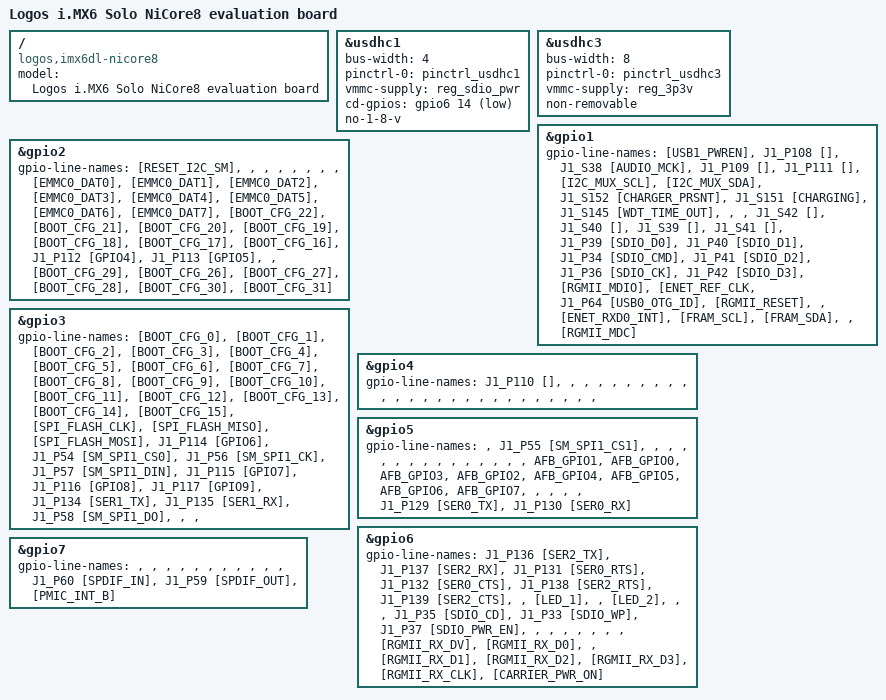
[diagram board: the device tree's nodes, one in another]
// SPDX-License-Identifier: GPL-2.0 OR X11
/*
 * Copyright 2015 Boundary Devices, Inc.
 * Copyright 2021 Logos Payment Solutions A/S
 */

/dts-v1/;

#include "imx6dl.dtsi"
#include "imx6qdl-nicore8.dtsi"

/ {
	model = "Logos i.MX6 Solo NiCore8 evaluation board";
	compatible = "logos,imx6dl-nicore8", "fsl,imx6dl";
};

/* USDHC1, SD Card */
&usdhc1 {
        pinctrl-names = "default";
        bus-width = <4>;
        pinctrl-0 = <&pinctrl_usdhc1>;
        vmmc-supply = <&reg_sdio_pwr>;
        cd-gpios = <&gpio6 14 GPIO_ACTIVE_LOW>;
	no-1-8-v;
        status = "okay";
};

/* USDHC3, eMMC */
&usdhc3 {
        pinctrl-names = "default";
        bus-width = <8>;
        pinctrl-0 = <&pinctrl_usdhc3>;
        vmmc-supply = <&reg_3p3v>;
        non-removable;
        status = "okay";
};

/* 
 * Purpose in GPIO naming below corresponds to schematic:
 * PCB17381-SCHE-401148-00 'PCB17381 NiCore8 SMARC 1.1 Module'
 * PCB18091-SCHE-401264-00 'PCB18091 SMARC Test Carrier'
 */

&gpio1 {
	gpio-line-names =
		"[USB1_PWREN]", // GPIO_0 GPIO1_IO00 0
		"J1_P108 []", // GPIO_1 GPIO1_IO01 1
		"J1_S38 [AUDIO_MCK]", // GPIO_2 GPIO1_IO02 2
		"J1_P109 []", // GPIO_3 GPIO1_IO03 3
		"J1_P111 []", // GPIO_4 GPIO1_IO04 4
		"[I2C_MUX_SCL]", // GPIO_5 GPIO1_IO05 5
		"[I2C_MUX_SDA]", // GPIO_6 GPIO1_IO06 6
		"J1_S152 [CHARGER_PRSNT]", // GPIO_7 GPIO1_IO07 7
		"J1_S151 [CHARGING]", // GPIO_8 GPIO1_IO08 8
		"J1_S145 [WDT_TIME_OUT]", // GPIO_9 GPIO1_IO09 9
		"", // SD2_CLK GPIO1_IO10 10
		"", // SD2_CMD GPIO1_IO11 11
		"J1_S42 []", // SD2_DAT3 GPIO1_IO12 12
		"J1_S40 []", // SD2_DAT2 GPIO1_IO13 13
		"J1_S39 []", // SD2_DAT1 GPIO1_IO14 14
		"J1_S41 []", // SD2_DAT0 GPIO1_IO15 15
		"J1_P39 [SDIO_D0]", // SD1_DAT0 GPIO1_IO16 16
		"J1_P40 [SDIO_D1]", // SD1_DAT1 GPIO1_IO17 17
		"J1_P34 [SDIO_CMD]", // SD1_CMD GPIO1_IO18 18
		"J1_P41 [SDIO_D2]", // SD1_DAT2 GPIO1_IO19 19
		"J1_P36 [SDIO_CK]", // SD1_CLK GPIO1_IO20 20
		"J1_P42 [SDIO_D3]", // SD1_DAT3 GPIO1_IO21 21
		"[RGMII_MDIO]", // ENET_MDIO GPIO1_IO22 22
		"[ENET_REF_CLK", // ENET_REF_CLK GPIO1_IO23 23
		"J1_P64 [USB0_OTG_ID]", // ENET_RX_ER GPIO1_IO24 24
		"[RGMII_RESET]", // ENET_CRS_DV GPIO1_IO25 25
		"", // ENET_RXD1 GPIO1_IO26 26
		"[ENET_RXD0_INT]", // ENET_RXD0 GPIO1_IO27 27
		"[FRAM_SCL]", // ENET_TX_EN GPIO1_IO28 28
		"[FRAM_SDA]", // ENET_TXD1 GPIO1_IO29 29
		"", // ENET_TXD0 GPIO1_IO30 30
		"[RGMII_MDC]"; // ENET_MDC GPIO1_IO31 31
};

&gpio2 {
	gpio-line-names =
		"[RESET_I2C_SM]", // NANDF_D0 GPIO2_IO00 32
		"", // NANDF_D1 GPIO2_IO01 33
		"", // NANDF_D2 GPIO2_IO02 34
		"", // NANDF_D3 GPIO2_IO03 35
		"", // NANDF_D4 GPIO2_IO04 36
		"", // NANDF_D5 GPIO2_IO05 37
		"", // NANDF_D6 GPIO2_IO06 38
		"", // NANDF_D7 GPIO2_IO07 39
		"[EMMC0_DAT0]", // SD4_DAT0 GPIO2_IO08 40
		"[EMMC0_DAT1]", // SD4_DAT1 GPIO2_IO09 41
		"[EMMC0_DAT2]", // SD4_DAT2 GPIO2_IO10 42
		"[EMMC0_DAT3]", // SD4_DAT3 GPIO2_IO11 43
		"[EMMC0_DAT4]", // SD4_DAT4 GPIO2_IO12 44
		"[EMMC0_DAT5]", // SD4_DAT5 GPIO2_IO13 45
		"[EMMC0_DAT6]", // SD4_DAT6 GPIO2_IO14 46
		"[EMMC0_DAT7]", // SD4_DAT7 GPIO2_IO15 47
		"[BOOT_CFG_22]", // EIM_A22 GPIO2_IO16 48
		"[BOOT_CFG_21]", // EIM_A21 GPIO2_IO17 49
		"[BOOT_CFG_20]", // EIM_A20 GPIO2_IO18 50
		"[BOOT_CFG_19]", // EIM_A19 GPIO2_IO19 51
		"[BOOT_CFG_18]", // EIM_A18 GPIO2_IO20 52
		"[BOOT_CFG_17]", // EIM_A17 GPIO2_IO21 53
		"[BOOT_CFG_16]", // EIM_A16 GPIO2_IO22 54
		"J1_P112 [GPIO4]", // EIM_CS0 GPIO2_IO23 55
		"J1_P113 [GPIO5]", // EIM_CS1 GPIO2_IO24 56
		"", // EIM_OE GPIO2_IO25 57
		"[BOOT_CFG_29]", // EIM_RW GPIO2_IO26 58
		"[BOOT_CFG_26]", // EIM_LBA GPIO2_IO27 59
		"[BOOT_CFG_27]", // EIM_EB0 GPIO2_IO28 60
		"[BOOT_CFG_28]", // EIM_EB1 GPIO2_IO29 61
		"[BOOT_CFG_30]", // EIM_EB2 GPIO2_IO30 62
		"[BOOT_CFG_31]"; // EIM_EB3 GPIO2_IO31 63
};

&gpio3 {
	gpio-line-names =
		"[BOOT_CFG_0]", // EIM_DA0 GPIO3_IO00 64
		"[BOOT_CFG_1]", // EIM_DA1 GPIO3_IO01 65
		"[BOOT_CFG_2]", // EIM_DA2 GPIO3_IO02 66
		"[BOOT_CFG_3]", // EIM_DA3 GPIO3_IO03 67
		"[BOOT_CFG_4]", // EIM_DA4 GPIO3_IO04 68
		"[BOOT_CFG_5]", // EIM_DA5 GPIO3_IO05 69
		"[BOOT_CFG_6]", // EIM_DA6 GPIO3_IO06 70
		"[BOOT_CFG_7]", // EIM_DA7 GPIO3_IO07 71
		"[BOOT_CFG_8]", // EIM_DA8 GPIO3_IO08 72
		"[BOOT_CFG_9]", // EIM_DA9 GPIO3_IO09 73
		"[BOOT_CFG_10]", // EIM_DA10 GPIO3_IO10 74
		"[BOOT_CFG_11]", // EIM_DA11 GPIO3_IO11 75
		"[BOOT_CFG_12]", // EIM_DA12 GPIO3_IO12 76
		"[BOOT_CFG_13]", // EIM_DA13 GPIO3_IO13 77
		"[BOOT_CFG_14]", // EIM_DA14 GPIO3_IO14 78
		"[BOOT_CFG_15]", // EIM_DA15 GPIO3_IO15 79
		"[SPI_FLASH_CLK]", // EIM_D16 GPIO3_IO16 80
		"[SPI_FLASH_MISO]", // EIM_D17 GPIO3_IO17 81
		"[SPI_FLASH_MOSI]", // EIM_D18 GPIO3_IO18 82
		"J1_P114 [GPIO6]", // EIM_D19 GPIO3_IO19 83
		"J1_P54 [SM_SPI1_CS0]", // EIM_D20 GPIO3_IO20 84
		"J1_P56 [SM_SPI1_CK]", // EIM_D21 GPIO3_IO21 85
		"J1_P57 [SM_SPI1_DIN]", // EIM_D22 GPIO3_IO22 86
		"J1_P115 [GPIO7]", // EIM_D23 GPIO3_IO23 87
		"J1_P116 [GPIO8]", // EIM_D24 GPIO3_IO24 88
		"J1_P117 [GPIO9]", // EIM_D25 GPIO3_IO25 89
		"J1_P134 [SER1_TX]", // EIM_D26 GPIO3_IO26 90
		"J1_P135 [SER1_RX]", // EIM_D27 GPIO3_IO27 91
		"J1_P58 [SM_SPI1_DO]", // EIM_D28 GPIO3_IO28 92
		"", // EIM_D29 GPIO3_IO29 93
		"", // EIM_D30 GPIO3_IO30 94
		""; // EIM_D31 GPIO3_IO31 95
};

&gpio4 {
	gpio-line-names =
		"J1_P110 []", // GPIO_19 GPIO4_IO05 101
		"", // KEY_COL0 GPIO4_IO06 102
		"", // KEY_ROW0 GPIO4_IO07 103
		"", // KEY_COL1 GPIO4_IO08 104
		"", // KEY_ROW1 GPIO4_IO09 105
		"", // KEY_COL2 GPIO4_IO10 106
		"", // KEY_ROW2 GPIO4_IO11 107
		"", // KEY_COL3 GPIO4_IO12 108
		"", // KEY_ROW3 GPIO4_IO13 109
		"", // KEY_COL4 GPIO4_IO14 110
		"", // KEY_ROW4 GPIO4_IO15 111
		"", // DI0_DISP_CLK GPIO4_IO16 112
		"", // DI0_PIN15 GPIO4_IO17 113
		"", // DI0_PIN2 GPIO4_IO18 114
		"", // DI0_PIN3 GPIO4_IO19 115
		"", // DI0_PIN4 GPIO4_IO20 116
		"", // DISP0_DAT0 GPIO4_IO21 117
		"", // DISP0_DAT1 GPIO4_IO22 118
		"", // DISP0_DAT2 GPIO4_IO23 119
		"", // DISP0_DAT3 GPIO4_IO24 120
		"", // DISP0_DAT4 GPIO4_IO25 121
		"", // DISP0_DAT5 GPIO4_IO26 122
		"", // DISP0_DAT6 GPIO4_IO27 123
		"", // DISP0_DAT7 GPIO4_IO28 124
		"", // DISP0_DAT8 GPIO4_IO29 125
		"", // DISP0_DAT9 GPIO4_IO30 126
		""; // DISP0_DAT10 GPIO4_IO31 127
};

&gpio5 {
	gpio-line-names =
		"", // EIM_WAIT GPIO5_IO00 128
		"J1_P55 [SM_SPI1_CS1]", // EIM_A25 GPIO5_IO02 130
		"", // EIM_A24 GPIO5_IO04 132
		"", // DISP0_DAT11 GPIO5_IO05 133
		"", // DISP0_DAT12 GPIO5_IO06 134
		"", // DISP0_DAT13 GPIO5_IO07 135
		"", // DISP0_DAT14 GPIO5_IO08 136
		"", // DISP0_DAT15 GPIO5_IO09 137
		"", // DISP0_DAT16 GPIO5_IO10 138
		"", // DISP0_DAT17 GPIO5_IO11 139
		"", // DISP0_DAT18 GPIO5_IO12 140
		"", // DISP0_DAT19 GPIO5_IO13 141
		"", // DISP0_DAT20 GPIO5_IO14 142
		"", // DISP0_DAT21 GPIO5_IO15 143
		"", // DISP0_DAT22 GPIO5_IO16 144
		"", // DISP0_DAT23 GPIO5_IO17 145
		"AFB_GPIO1", // CSI0_PIXCLK GPIO5_IO18 146
		"AFB_GPIO0", // CSI0_MCLK GPIO5_IO19 147
		"AFB_GPIO3", // CSI0_DATA_EN GPIO5_IO20 148
		"AFB_GPIO2", // CSI0_VSYNC GPIO5_IO21 149
		"AFB_GPIO4", // CSI0_DAT4 GPIO5_IO22 150
		"AFB_GPIO5", // CSI0_DAT5 GPIO5_IO23 151
		"AFB_GPIO6", // CSI0_DAT6 GPIO5_IO24 152
		"AFB_GPIO7", // CSI0_DAT7 GPIO5_IO25 153
		"", // CSI0_DAT8 GPIO5_IO26 154
		"", // CSI0_DAT9 GPIO5_IO27 155
		"", // CSI0_DAT10 GPIO5_IO28 156
		"", // CSI0_DAT11 GPIO5_IO29 157
		"J1_P129 [SER0_TX]", // CSI0_DAT12 GPIO5_IO30 158
		"J1_P130 [SER0_RX]"; // CSI0_DAT13 GPIO5_IO31 159
};

&gpio6 {
	gpio-line-names =
		"J1_P136 [SER2_TX]", // CSI0_DAT14 GPIO6_IO00 160
		"J1_P137 [SER2_RX]", // CSI0_DAT15 GPIO6_IO01 161
		"J1_P131 [SER0_RTS]", // CSI0_DAT16 GPIO6_IO02 162
		"J1_P132 [SER0_CTS]", // CSI0_DAT17 GPIO6_IO03 163
		"J1_P138 [SER2_RTS]", // CSI0_DAT18 GPIO6_IO04 164
		"J1_P139 [SER2_CTS]", // CSI0_DAT19 GPIO6_IO05 165
		"", // EIM_A23 GPIO6_IO06 166
		"[LED_1]", // NANDF_CLE GPIO6_IO07 167
		"", // NANDF_ALE GPIO6_IO08 168
		"[LED_2]", // NANDF_WP_B GPIO6_IO09 169
		"", // NANDF_RB0 GPIO6_IO10 170
		"", // NANDF_CS0 GPIO6_IO11 171
		"J1_P35 [SDIO_CD]", // NANDF_CS1 GPIO6_IO14 174
		"J1_P33 [SDIO_WP]", // NANDF_CS2 GPIO6_IO15 175
		"J1_P37 [SDIO_PWR_EN]", // NANDF_CS3 GPIO6_IO16 176
		"", // SD3_DAT7 GPIO6_IO17 177
		"", // SD3_DAT6 GPIO6_IO18 178
		"", // RGMII_TXC GPIO6_IO19 179
		"", // RGMII_TD0 GPIO6_IO20 180
		"", // RGMII_TD1 GPIO6_IO21 181
		"", // RGMII_TD2 GPIO6_IO22 182
		"", // RGMII_TD3 GPIO6_IO23 183
		"[RGMII_RX_DV]", // RGMII_RX_CTL GPIO6_IO24 184
		"[RGMII_RX_D0]", // RGMII_RD0 GPIO6_IO25 185
		"", // RGMII_TX_CTL GPIO6_IO26 186
		"[RGMII_RX_D1]", // RGMII_RD1 GPIO6_IO27 187
		"[RGMII_RX_D2]", // RGMII_RD2 GPIO6_IO28 188
		"[RGMII_RX_D3]", // RGMII_RD3 GPIO6_IO29 189
		"[RGMII_RX_CLK]", // RGMII_RXC GPIO6_IO30 190
		"[CARRIER_PWR_ON]"; // EIM_BCLK GPIO6_IO31 191
};

&gpio7 {
	gpio-line-names =
		"", // SD3_DAT5 GPIO7_IO00 192
		"", // SD3_DAT4 GPIO7_IO01 193
		"", // SD3_CMD GPIO7_IO02 194
		"", // SD3_CLK GPIO7_IO03 195
		"", // SD3_DAT0 GPIO7_IO04 196
		"", // SD3_DAT1 GPIO7_IO05 197
		"", // SD3_DAT2 GPIO7_IO06 198
		"", // SD3_DAT3 GPIO7_IO07 199
		"", // SD3_RST GPIO7_IO08 200
		"", // SD4_CMD GPIO7_IO09 201
		"", // SD4_CLK GPIO7_IO10 202
		"J1_P60 [SPDIF_IN]", // GPIO_16 GPIO7_IO11 203
		"J1_P59 [SPDIF_OUT]", // GPIO_17 GPIO7_IO12 204
		"[PMIC_INT_B]"; // GPIO_18 GPIO7_IO13 205
};

